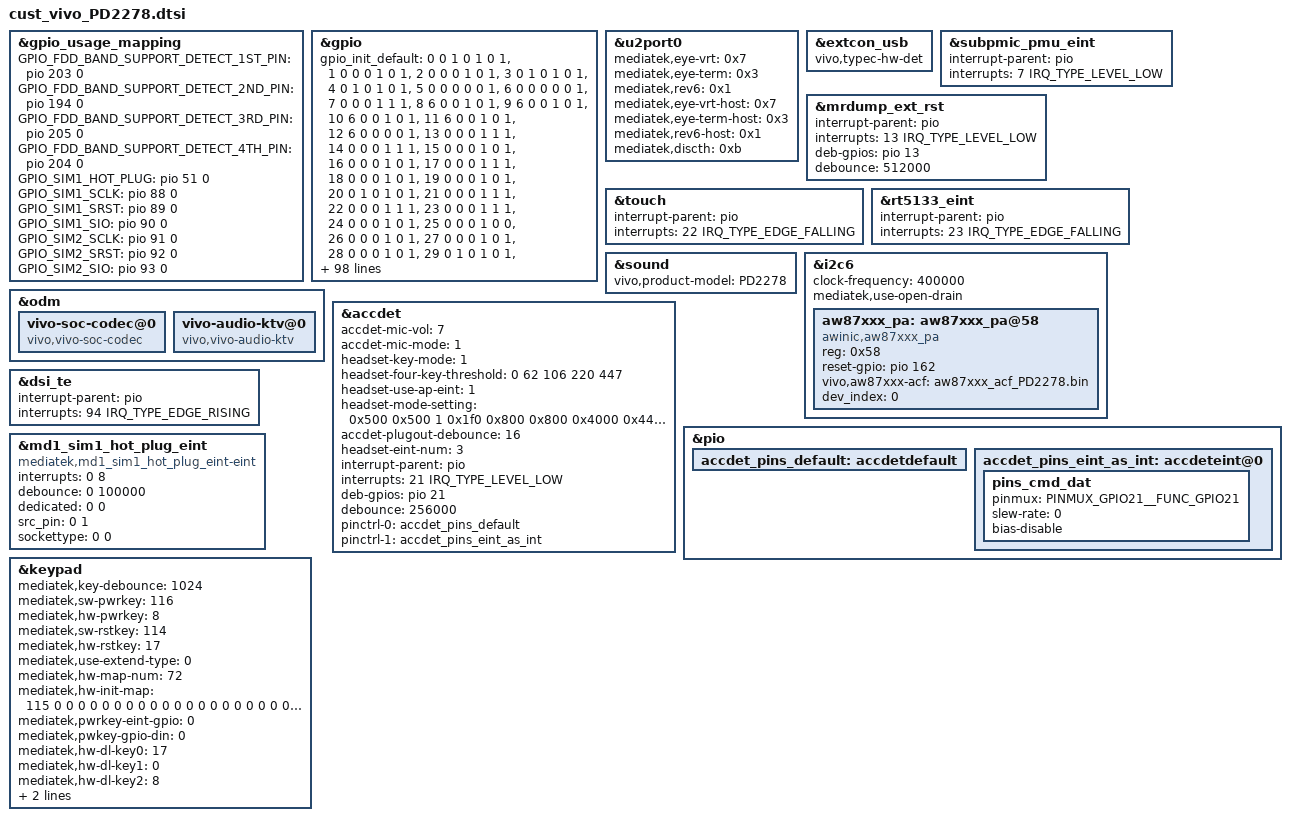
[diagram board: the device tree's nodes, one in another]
/*
 * Generated by MTK SP DrvGen Version: 3.5.160809 for MT6855.
 * 2022-03-10 18:09:54
 * Do Not Modify The File.
 * Copyright Mediatek Inc. (c) 2016.
*/

/*************************
 * ADC DTSI File
*************************/



/*************************
 * CLK_BUF DTSI File
*************************/



/*************************
 * I2C DTSI File
*************************/



/*************************
 * GPIO DTSI File
*************************/

&gpio_usage_mapping {
	GPIO_FDD_BAND_SUPPORT_DETECT_1ST_PIN = <&pio 203 0>;
	GPIO_FDD_BAND_SUPPORT_DETECT_2ND_PIN = <&pio 194 0>;
	GPIO_FDD_BAND_SUPPORT_DETECT_3RD_PIN = <&pio 205 0>;
	GPIO_FDD_BAND_SUPPORT_DETECT_4TH_PIN = <&pio 204 0>;
	GPIO_SIM1_HOT_PLUG = <&pio 51 0>;
	//GPIO_SIM2_HOT_PLUG = <&pio 52 0>;
	GPIO_SIM1_SCLK = <&pio 88 0>;
	GPIO_SIM1_SRST = <&pio 89 0>;
	GPIO_SIM1_SIO = <&pio 90 0>;
	GPIO_SIM2_SCLK = <&pio 91 0>;
	GPIO_SIM2_SRST = <&pio 92 0>;
	GPIO_SIM2_SIO = <&pio 93 0>;

};

&gpio{
	gpio_init_default = <0 0 1 0 1 0 1>,
		<1 0 0 0 1 0 1>,
		<2 0 0 0 1 0 1>,
		<3 0 1 0 1 0 1>,
		<4 0 1 0 1 0 1>,
		<5 0 0 0 0 0 1>,
		<6 0 0 0 0 0 1>,
		<7 0 0 0 1 1 1>,
		<8 6 0 0 1 0 1>,
		<9 6 0 0 1 0 1>,
		<10 6 0 0 1 0 1>,
		<11 6 0 0 1 0 1>,
		<12 6 0 0 0 0 1>,
		<13 0 0 0 1 1 1>,
		<14 0 0 0 1 1 1>,
		<15 0 0 0 1 0 1>,
		<16 0 0 0 1 0 1>,
		<17 0 0 0 1 1 1>,
		<18 0 0 0 1 0 1>,
		<19 0 0 0 1 0 1>,
		<20 0 1 0 1 0 1>,
		<21 0 0 0 1 1 1>, //headset_det irq, gpio mode, input, pull_up, schmitt-enable
		<22 0 0 0 1 1 1>,
		<23 0 0 0 1 1 1>,
		<24 0 0 0 1 0 1>,
		<25 0 0 0 1 0 0>,
		<26 0 0 0 1 0 1>,
		<27 0 0 0 1 0 1>,
		<28 0 0 0 1 0 1>,
		<29 0 1 0 1 0 1>,
		<30 0 1 0 1 0 1>,
		<31 0 1 0 1 0 1>,
		<32 0 1 0 1 0 1>,
		<33 0 0 0 1 0 1>,
		<34 0 0 0 1 0 1>,
		<35 3 0 0 1 1 1>,
		<36 0 0 0 1 1 0>,
		<37 3 0 0 0 0 1>,
		<38 0 0 0 1 1 0>,
		<39 0 0 0 1 0 1>,
		<40 0 0 0 1 0 0>,
		<41 0 0 0 1 0 0>,
		<42 0 0 0 1 1 0>,
		<43 0 0 0 1 0 0>,
		<44 0 0 0 1 0 0>,
		<45 0 0 0 1 0 0>,
		<46 0 0 0 1 1 1>,
		<47 1 0 0 0 0 1>,
		<48 1 0 0 0 0 1>,
		<49 1 0 0 0 0 1>,
		<50 3 0 0 1 0 1>,
		<51 1 0 0 0 0 1>,
		<52 0 0 0 0 0 1>,
		<53 1 0 0 0 0 1>,
		<54 1 0 0 1 1 1>,
		<55 1 0 0 0 0 1>,
		<56 1 0 0 1 1 1>,
		<57 1 0 0 1 0 1>,
		<58 0 1 0 1 0 1>,
		<59 1 0 0 1 1 1>,
		<60 7 0 0 1 0 1>,
		<61 7 0 0 1 0 1>,
		<62 7 0 0 1 0 1>,
		<63 7 0 0 0 0 1>,
		<64 7 0 0 1 0 1>,
		<65 0 1 0 1 0 1>,
		<66 0 1 0 1 0 1>,
		<67 0 1 0 1 0 1>,
		<68 0 1 0 1 0 1>,
		<69 1 0 0 0 0 1>,
		<70 1 0 0 0 0 1>,
		<71 1 0 0 0 0 1>,
		<72 1 0 0 1 0 1>,
		<73 2 0 0 0 0 1>,
		<74 2 0 0 0 0 1>,
		<75 2 0 0 0 0 1>,
		<76 2 0 0 1 0 1>,
		<77 1 0 0 0 0 1>,
		<78 1 0 0 0 0 1>,
		<79 1 0 0 0 0 1>,
		<80 1 0 0 1 0 1>,
		<82 1 0 0 0 0 1>,
		<83 1 0 0 1 1 1>,
		<84 1 0 0 1 1 1>,
		<85 1 0 0 1 1 1>,
		<86 1 0 0 1 1 1>,
		<87 1 0 0 1 1 1>,
		<88 1 0 0 0 0 1>,
		<89 1 0 0 0 0 1>,
		<90 1 0 0 1 1 1>,
		<91 1 0 0 0 0 1>,
		<92 1 0 0 0 0 1>,
		<93 1 0 0 1 1 1>,
		<94 1 0 0 1 0 1>,
		<95 0 1 0 0 0 0>,
		<96 1 0 0 0 0 1>,
		<97 1 1 0 0 0 1>,
		<98 1 1 0 0 0 1>,
		<99 1 1 0 0 0 1>,
		<100 1 0 0 1 0 1>,
		<101 0 0 0 0 0 1>,
		<102 0 0 0 0 0 1>,
		<103 1 0 0 1 0 1>,
		<104 1 0 0 1 0 1>,
		<105 1 0 0 0 0 1>,
		<106 1 0 0 0 0 1>,
		<107 0 0 0 1 1 0>,
		<108 1 0 0 0 0 1>,
		<109 1 0 0 0 0 1>,
		<110 1 0 0 0 0 1>,
		<111 1 0 0 0 0 1>,
		<112 0 0 0 1 1 0>,
		<113 0 0 0 1 1 0>,
		<114 1 0 0 0 0 1>,
		<115 1 0 0 0 0 1>,
		<116 1 0 0 0 0 1>,
		<117 1 0 0 0 0 1>,
		<118 0 1 0 0 0 1>,
		<119 0 0 0 1 1 0>,
		<120 1 0 0 0 0 1>,
		<121 1 0 0 0 0 1>,
		<122 1 0 0 0 0 1>,
		<123 0 1 0 0 0 1>,
		<124 1 0 0 0 0 1>,
		<125 1 0 0 0 0 1>,
		<126 1 0 0 0 0 1>,
		<127 1 0 0 0 0 0>,
		<128 1 0 0 1 0 0>,
		<129 1 0 0 0 0 0>,
		<130 1 0 0 1 0 0>,
		<131 1 0 0 0 0 0>,
		<132 1 0 0 1 0 0>,
		<133 3 0 0 1 0 1>,
		<134 0 1 0 0 0 0>,
		<135 1 0 0 1 0 1>,
		<136 1 0 0 1 0 1>,
		<137 1 0 0 1 1 1>,
		<138 1 0 0 1 1 1>,
		<139 2 0 0 1 1 1>,
		<140 2 0 0 1 1 1>,
		<141 1 0 0 1 1 1>,
		<142 1 0 0 1 1 1>,
		<143 1 0 0 1 1 1>,
		<144 1 0 0 1 1 1>,
		<145 1 0 0 1 1 1>,
		<146 1 0 0 1 1 1>,
		<147 1 0 0 1 1 1>,
		<148 1 0 0 1 1 1>,
		<149 1 0 0 1 1 1>, //audio I2C6, i2c mode, internal pull-up
		<150 1 0 0 1 1 1>, //audio I2C6, i2c mode, internal pull-up
		<151 1 0 0 1 1 1>,
		<152 1 0 0 1 1 1>,
		<153 1 0 0 1 1 1>,
		<154 1 0 0 1 1 1>,
		<155 1 0 0 1 1 1>,
		<156 1 0 0 1 1 1>,
		<157 0 1 0 1 0 1>,
		<158 0 0 0 1 0 1>,
		<159 0 0 0 1 0 1>,
		<160 0 0 0 1 0 1>,
		<161 0 1 0 1 0 1>,
		<162 0 1 0 0 0 0>, // audio PA rst, gpio mode, output-low, no-pull
		<163 1 0 0 0 0 1>,
		<164 1 0 0 0 0 1>,
		<165 1 0 0 0 0 1>,
		<166 1 0 0 0 0 1>,
		<167 1 0 0 0 0 1>,
		<168 1 0 0 0 0 1>,
		<169 1 0 0 0 0 1>,
		<170 1 0 0 1 0 1>,
		<171 1 0 0 0 0 1>,
		<172 1 0 0 0 0 1>,
		<173 1 0 0 0 0 1>,
		<174 1 0 0 0 0 1>,
		<175 1 0 0 0 0 1>,
		<176 1 0 0 0 0 1>,
		<177 1 0 0 0 0 1>,
		<178 1 0 0 0 0 1>,
		<179 1 0 0 1 0 1>,
		<180 1 0 0 1 0 1>,
		<181 1 0 0 1 0 1>,
		<182 0 1 0 0 0 0>,
		<183 0 1 0 0 0 0>,
		<184 0 0 0 1 0 1>,
		<185 0 0 0 1 0 1>,
		<186 0 0 0 1 0 1>,
		<187 0 0 0 1 0 1>,
		<188 0 0 0 1 0 1>,
		<189 0 0 0 1 0 1>,
		<190 0 0 0 1 0 1>,
		<191 0 0 0 1 0 1>,
		<192 0 0 0 1 0 1>,
		<193 1 0 0 0 0 1>,
		<194 0 0 0 1 1 0>,
		<195 1 0 0 0 0 1>,
		<196 1 0 0 1 1 1>,
		<197 1 0 0 0 0 1>,
		<198 0 0 0 1 1 0>,
		<199 0 0 0 1 1 0>,
		<200 0 0 0 1 1 0>,
		<201 0 1 0 0 0 1>,
		<202 1 0 0 1 1 1>,
		<203 0 0 0 1 1 0>,
		<204 0 0 0 1 1 0>,
		<205 0 0 0 1 1 0>,
		<206 0 0 0 1 0 0>,
		<207 0 0 0 1 0 0>,
		<208 0 0 0 1 0 0>,
		<209 0 0 0 1 0 0>,
		<210 0 0 0 1 0 0>,
		<211 0 0 0 1 0 0>,
		<212 0 0 0 1 0 0>,
		<213 0 0 0 1 0 0>,
		<214 0 0 0 1 0 0>,
		<215 0 0 0 1 0 0>,
		<216 0 0 0 1 0 0>,
		<217 0 0 0 1 0 0>,
		<218 0 0 0 1 0 0>,
		<219 0 0 0 1 0 0>,
		<220 0 0 0 1 0 0>,
		<221 0 0 0 1 0 0>,
		<222 0 0 0 1 0 0>,
		<223 0 0 0 1 0 0>,
		<224 0 0 0 1 0 0>,
		<225 0 0 0 1 0 0>;
};

/* add usb config by vivo USB team begin */
&u2port0 {
	mediatek,eye-vrt = <0x7>;
	mediatek,eye-term = <0x3>;
	mediatek,rev6 = <0x1>;
	mediatek,eye-vrt-host = <0x7>;
	mediatek,eye-term-host = <0x3>;
	mediatek,rev6-host = <0x1>;
	mediatek,discth = <0xb>;
};

&extcon_usb {
	vivo,typec-hw-det;
};

/* add usb config by vivo USB team end */

/*************************
 * EINT DTSI File
*************************/

#include <dt-bindings/interrupt-controller/irq.h>
#include <dt-bindings/interrupt-controller/arm-gic.h>

&subpmic_pmu_eint {
	interrupt-parent = <&pio>;
	interrupts = <7 IRQ_TYPE_LEVEL_LOW>;
	status = "okay";
};

&mrdump_ext_rst {
	interrupt-parent = <&pio>;
	interrupts = <13 IRQ_TYPE_LEVEL_LOW>;
	deb-gpios = <&pio 13 0>;
	debounce = <512000>;
	status = "okay";
};

&touch {
	interrupt-parent = <&pio>;
	interrupts = <22 IRQ_TYPE_EDGE_FALLING>;
	status = "okay";
};

&rt5133_eint {
	interrupt-parent = <&pio>;
	interrupts = <23 IRQ_TYPE_EDGE_FALLING>;
	status = "okay";
};

/* vivo audio add begin */
&sound {
		vivo,product-model = "PD2278";
};

&i2c6{
	status = "okay";
	#address-cells = <1>;
	#size-cells = <0>;
	clock-frequency = <400000>;  /* must 400k */
	mediatek,use-open-drain;

	aw87xxx_pa: aw87xxx_pa@58 {
		compatible = "awinic,aw87xxx_pa";
		reg = <0x58>;
		reset-gpio = <&pio 162 0>;
		vivo,aw87xxx-acf = "aw87xxx_acf_PD2278.bin";
		dev_index = <0>;
		status = "okay";
	};
};

&odm {
	vivo-soc-codec@0 {
 		compatible = "vivo,vivo-soc-codec";
 		status = "okay";
 	};
	vivo-audio-ktv@0 {
		compatible = "vivo,vivo-audio-ktv";
		status = "okay";
	};
};

&accdet {
	accdet-mic-vol = <7>; //2.7v
	accdet-mic-mode = <1>; //ACC
	headset-key-mode = <1>; //0:ACCDET_THREE_KEY 1:ACCDET_FOUR_KEY
	headset-four-key-threshold = <0 62 106 220 447>; 
	headset-use-ap-eint = <1>; //0:ACCDET_PMIC_EINT_IRQ 1:ACCDET_AP_GPIO_EINT
	headset-mode-setting = <0x500 0x500 1 0x1f0
				0x800 0x800 0x4000 0x44
				0x4 0x1
				0x5 0x3 0x3 0x5 0xe>;
	accdet-plugout-debounce = <16>;
	headset-eint-num = <3>;//disable ACCDET_PMIC_EINT0
	interrupt-parent = <&pio>;
	interrupts = <21 IRQ_TYPE_LEVEL_LOW>;
	interrupt-names = "ap_eint";
	deb-gpios = <&pio 21 0>;
	debounce = <256000>;
	pinctrl-names = "default", "state_eint_as_int";
	pinctrl-0 = <&accdet_pins_default>;
	pinctrl-1 = <&accdet_pins_eint_as_int>;
	status = "okay";
};


&pio {
	accdet_pins_default: accdetdefault {
	};
	accdet_pins_eint_as_int: accdeteint@0 {
		pins_cmd_dat {
			pinmux = <PINMUX_GPIO21__FUNC_GPIO21>;
			slew-rate = <0>;
			bias-disable;
		};
	};
};

/* vivo audio add end */

&dsi_te {
	interrupt-parent = <&pio>;
	interrupts = <94 IRQ_TYPE_EDGE_RISING>;
	status = "okay";
};



/*************************
 * MD1_EINT DTSI File
*************************/

&md1_sim1_hot_plug_eint {
	compatible = "mediatek,md1_sim1_hot_plug_eint-eint";
	interrupts = <0 8>;
	debounce = <0 100000>;
	dedicated = <0 0>;
	src_pin = <0 1>;
	sockettype = <0 0>;
	status = "okay";
};




/*************************
 * PMIC DTSI File
*************************/



/*************************
 * POWER DTSI File
*************************/



/*************************
 * KPD DTSI File
*************************/

&keypad {
	mediatek,key-debounce = <1024>;
	mediatek,sw-pwrkey = <116>;
	mediatek,hw-pwrkey = <8>;
	mediatek,sw-rstkey  = <114>;
	mediatek,hw-rstkey = <17>;
	mediatek,use-extend-type = <0>;
	/*HW Keycode [0~71] -> Linux Keycode*/
	mediatek,hw-map-num = <72>;
	mediatek,hw-init-map = <115 0 0 0 0 0 0 0 0 0 0 0 0 0 0 0 0 0 0 0 0 0 0 0 0 0 0 0 0 0 0 0 0 0 0 0 0 0 0 0 0 0 0 0 0 0 0 0 0 0 0 0 0 0 0 0 0 0 0 0 0 0 0 0 0 0 0 0 0 0 0 0 >;
	mediatek,pwrkey-eint-gpio = <0>;
	mediatek,pwkey-gpio-din  = <0>;
	mediatek,hw-dl-key0 = <17>;
	mediatek,hw-dl-key1 = <0>;
	mediatek,hw-dl-key2 = <8>;
	mediatek,hw-recovery-key = <17>;
	mediatek,hw-factory-key = <0>;
	status = "okay";
};



